AUTOSAR XML (schema 4-3-0)
package /ComponentTypes
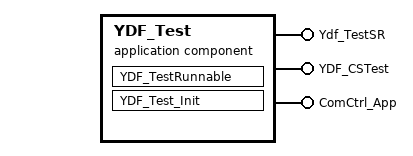
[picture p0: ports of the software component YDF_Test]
  application sw component type YDF_Test
    provide port Ydf_TestSR: provided-com-specs=[{data-element=TestSender1, init-value=0}, {data-element=TestSender2, init-value=0}], provided-interface=Ydf_TestSR
    provide port YDF_CSTest: server-com-spec{operation=Element, queue-length=1}, provided-interface=YDF_CSTest
    provide port ComCtrl_App: nonqueued-sender-com-spec{data-element=ComState, init-value=0}, provided-interface=ComCtrl_App
    behavior YDF_Test_InternalBehavior
      operation invoked event OIT_YDF_TestRunnable_YDF_CSTest_Element: start-on-event=YDF_TestRunnable, operation=YDF_CSTest.Element
      init event YDF_Test_InitEvent: start-on-event=YDF_Test_Init
      runnable YDF_TestRunnable
        data-send-points:
          access SEND_Ydf_TestSR_TestSender1: accessed-variable=Ydf_TestSR.TestSender1
          access SEND_Ydf_TestSR_TestSender2: accessed-variable=Ydf_TestSR.TestSender2
      runnable YDF_Test_Init
        data-send-points:
          access SEND_ComCtrl_App_ComState: accessed-variable=ComCtrl_App.ComState
  swc implementation YDF_Test_Implementation: behavior=YDF_Test_InternalBehavior
